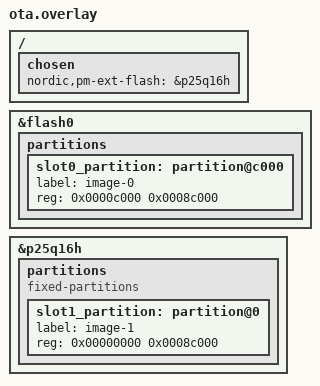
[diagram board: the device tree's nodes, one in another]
/*
 * OTA variant, app side (ADR 0015); same nodes as sysbuild/mcuboot.overlay. The Partition
 * Manager (ota/pm_static.yml) sets the real layout; the MCUboot and image-signing builds still
 * look up these labels to learn each slot's flash device and erase size.
 */
/ {
	chosen {
		nordic,pm-ext-flash = &p25q16h;
	};
};

&flash0 {
	partitions {
		slot0_partition: partition@c000 {
			label = "image-0";
			reg = <0x0000c000 0x0008c000>;
		};
	};
};

&p25q16h {
	partitions {
		compatible = "fixed-partitions";
		#address-cells = <1>;
		#size-cells = <1>;

		slot1_partition: partition@0 {
			label = "image-1";
			reg = <0x00000000 0x0008c000>;
		};
	};
};
